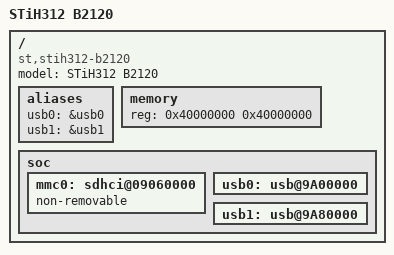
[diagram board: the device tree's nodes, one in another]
/*
 * Copyright (C) 2015 STMicroelectronics (R&D) Limited.
 * Author: Gabriel Fernandez <gabriel.fernandez@st.com>
 *
 * This program is free software; you can redistribute it and/or modify
 * it under the terms of the GNU General Public License version 2 as
 * published by the Free Software Foundation.
 */
/dts-v1/;
#include "stih412.dtsi"
#include "stihxxx-b2120.dtsi"
/ {
	model = "STiH312 B2120";
	compatible = "st,stih312-b2120", "st,stih310", "st,stih410";

	aliases {
		usb0 = &usb0;
		usb1 = &usb1;
	};

	memory {
		device_type = "memory";
		reg = <0x40000000 0x40000000>;
	};

	soc {
		mmc0: sdhci@09060000 {
			status = "okay";
			non-removable;
		};

		usb0: usb@9A00000 {
			status = "okay";
		};

		usb1: usb@9A80000 {
			status = "okay";
		};
	};
};
